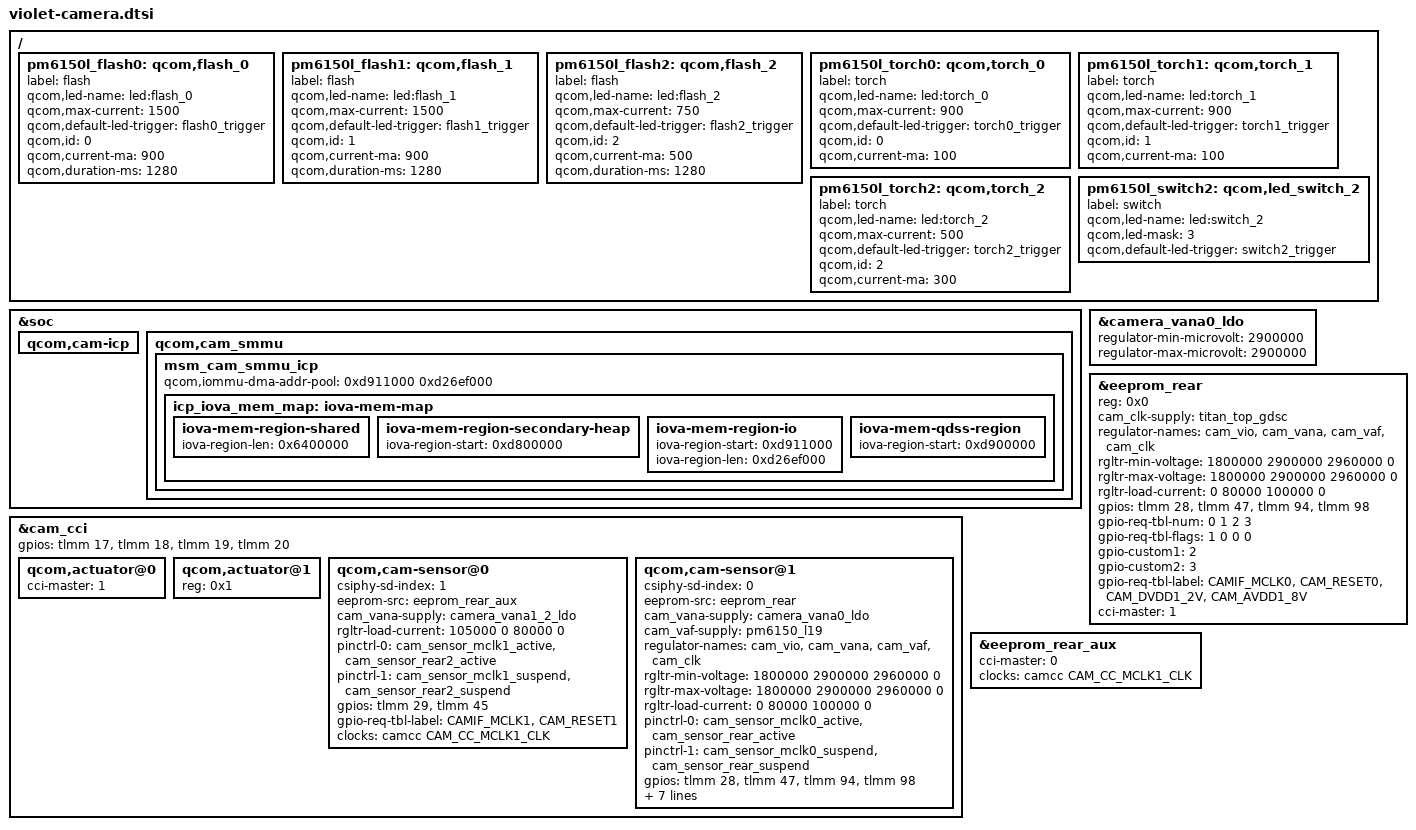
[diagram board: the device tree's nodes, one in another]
// SPDX-License-Identifier: GPL-2.0-only
/* violet camera: overrides of the sm6150 IDP sensor nodes, from the 4.14 violet-sm6150-camera.dtsi */

&soc {
	qcom,cam-icp {
		/delete-property/ icp_pc_en;
	};

	qcom,cam_smmu {
		msm_cam_smmu_icp {
			qcom,iommu-dma-addr-pool = <0xd911000 0xd26ef000>;
			icp_iova_mem_map: iova-mem-map {
				iova-mem-region-shared {
					iova-region-len = <0x6400000>;
				};

				iova-mem-region-secondary-heap {
					iova-region-start = <0xd800000>;
				};

				iova-mem-region-io {
					iova-region-start = <0xd911000>;
					iova-region-len = <0xd26ef000>;
				};

				iova-mem-qdss-region {
					iova-region-start = <0xd900000>;
				};
			};
		};
	};
};

&camera_vana0_ldo {
	regulator-min-microvolt = <2900000>;
	regulator-max-microvolt = <2900000>;
};

&cam_cci {
	gpios = <&tlmm 17 0>,
		<&tlmm 18 0>,
		<&tlmm 19 0>,
		<&tlmm 20 0>;

	qcom,actuator@0 {
		cci-master = <1>;
	};

	qcom,actuator@1 {
		reg = <0x1>;
	};


	qcom,cam-sensor@0 {
		csiphy-sd-index = <1>;
		eeprom-src = <&eeprom_rear_aux>;
		cam_vana-supply = <&camera_vana1_2_ldo>;
		rgltr-load-current = <105000 0 80000 0>;
		pinctrl-0 = <&cam_sensor_mclk1_active
					&cam_sensor_rear2_active>;
		pinctrl-1 = <&cam_sensor_mclk1_suspend
					&cam_sensor_rear2_suspend>;
		gpios = <&tlmm 29 0>,
				<&tlmm 45 0>;
		gpio-req-tbl-label = "CAMIF_MCLK1",
						"CAM_RESET1";
		clocks = <&camcc CAM_CC_MCLK1_CLK>;
	};

	qcom,cam-sensor@1 {
		csiphy-sd-index = <0>;
		eeprom-src = <&eeprom_rear>;
		cam_vana-supply = <&camera_vana0_ldo>;
		/delete-property/ cam_vdig-supply;
		cam_vaf-supply = <&pm6150_l19>;
		regulator-names = "cam_vio", "cam_vana", "cam_vaf","cam_clk";
		rgltr-min-voltage = <1800000 2900000 2960000 0>;
		rgltr-max-voltage = <1800000 2900000 2960000 0>;
		rgltr-load-current = <0 80000 100000 0>;
		pinctrl-0 = <&cam_sensor_mclk0_active
					&cam_sensor_rear_active>;
		pinctrl-1 = <&cam_sensor_mclk0_suspend
					&cam_sensor_rear_suspend>;
		gpios = <&tlmm 28 0>,
				<&tlmm 47 0>,
			<&tlmm 94 0>,
			<&tlmm 98 0>;
		gpio-req-tbl-num = <0 1 2 3>;
		gpio-req-tbl-flags = <1 0 0 0>;
			gpio-req-tbl-label = "CAMIF_MCLK0",
						"CAM_RESET0",
			"CAM_DVDD1_2V",
			"CAM_AVDD1_8V";
		gpio-custom1 = <2>;
		gpio-custom2 = <3>;
		clocks = <&camcc CAM_CC_MCLK0_CLK>;
	};

};

&eeprom_rear {
	reg = <0x0>;
	/delete-property/ cam_vdig-supply;
	cam_clk-supply = <&titan_top_gdsc>;
	regulator-names = "cam_vio", "cam_vana", "cam_vaf",
		"cam_clk";
	rgltr-min-voltage = <1800000 2900000 2960000 0>;
	rgltr-max-voltage = <1800000 2900000 2960000 0>;
	rgltr-load-current = <0 80000 100000 0>;
	gpios = <&tlmm 28 0>,
			<&tlmm 47 0>,
		<&tlmm 94 0>,
		<&tlmm 98 0>;
	gpio-req-tbl-num = <0 1 2 3>;
	gpio-req-tbl-flags = <1 0 0 0>;
	gpio-custom1 = <2>;
	gpio-custom2 = <3>;
	gpio-req-tbl-label = "CAMIF_MCLK0",
					"CAM_RESET0",
		"CAM_DVDD1_2V",
		"CAM_AVDD1_8V";
	cci-master = <1>;
};

&eeprom_rear_aux {
	cci-master = <0>;
	clocks = <&camcc CAM_CC_MCLK1_CLK>;
};

/*
 * The camera flash nodes point at the PMIC flash LEDs. There is no
 * flash LED driver on 6.1 yet, so these carry only what the camera
 * driver reads: the LED trigger names and currents (violet values).
 */
/ {
	pm6150l_flash0: qcom,flash_0 {
		label = "flash";
		qcom,led-name = "led:flash_0";
		qcom,max-current = <1500>;
		qcom,default-led-trigger = "flash0_trigger";
		qcom,id = <0>;
		qcom,current-ma = <900>;
		qcom,duration-ms = <1280>;
	};

	pm6150l_flash1: qcom,flash_1 {
		label = "flash";
		qcom,led-name = "led:flash_1";
		qcom,max-current = <1500>;
		qcom,default-led-trigger = "flash1_trigger";
		qcom,id = <1>;
		qcom,current-ma = <900>;
		qcom,duration-ms = <1280>;
	};

	pm6150l_flash2: qcom,flash_2 {
		label = "flash";
		qcom,led-name = "led:flash_2";
		qcom,max-current = <750>;
		qcom,default-led-trigger = "flash2_trigger";
		qcom,id = <2>;
		qcom,current-ma = <500>;
		qcom,duration-ms = <1280>;
	};

	pm6150l_torch0: qcom,torch_0 {
		label = "torch";
		qcom,led-name = "led:torch_0";
		qcom,max-current = <900>;
		qcom,default-led-trigger = "torch0_trigger";
		qcom,id = <0>;
		qcom,current-ma = <100>;
	};

	pm6150l_torch1: qcom,torch_1 {
		label = "torch";
		qcom,led-name = "led:torch_1";
		qcom,max-current = <900>;
		qcom,default-led-trigger = "torch1_trigger";
		qcom,id = <1>;
		qcom,current-ma = <100>;
	};

	pm6150l_torch2: qcom,torch_2 {
		label = "torch";
		qcom,led-name = "led:torch_2";
		qcom,max-current = <500>;
		qcom,default-led-trigger = "torch2_trigger";
		qcom,id = <2>;
		qcom,current-ma = <300>;
	};

	pm6150l_switch2: qcom,led_switch_2 {
		label = "switch";
		qcom,led-name = "led:switch_2";
		qcom,led-mask = <3>;
		qcom,default-led-trigger = "switch2_trigger";
	};
};
